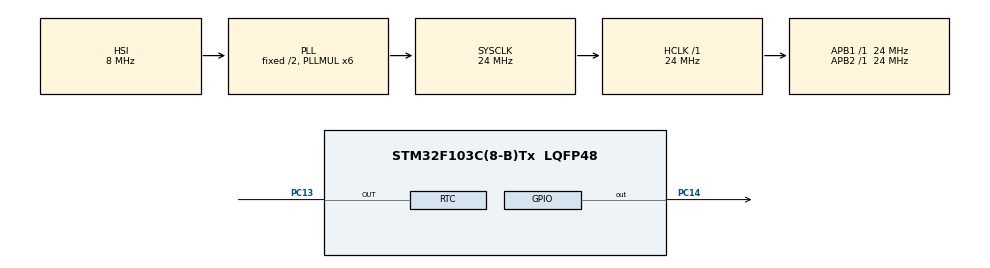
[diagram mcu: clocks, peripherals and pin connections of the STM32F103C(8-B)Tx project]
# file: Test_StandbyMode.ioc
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Mcu.Family=STM32F1
Mcu.Name=STM32F103C(8-B)Tx
Mcu.Package=LQFP48
NVIC.PriorityGroup=NVIC_PRIORITYGROUP_4
PA0-WKUP.Mode=SYS_WakeUp0
PA0-WKUP.Signal=SYS_WKUP
PA13.Mode=Serial_Wire
PA13.Signal=SYS_JTMS-SWDIO
PA14.Mode=Serial_Wire
PA14.Signal=SYS_JTCK-SWCLK
PC13-TAMPER-RTC.Mode=RTC OUT
PC13-TAMPER-RTC.Signal=RTC_OUT
PC14-OSC32_IN.Signal=GPIO_Output
ProjectManager.HeapSize=0x200
ProjectManager.StackSize=0x400
ProjectManager.TargetToolchain=MDK-ARM V5
RCC.AHBFreq_Value=24000000
RCC.APB1Freq_Value=24000000
RCC.APB1TimFreq_Value=24000000
RCC.APB2Freq_Value=24000000
RCC.APB2TimFreq_Value=24000000
RCC.HCLKFreq_Value=24000000
RCC.PLLMUL=RCC_PLL_MUL6
RCC.SYSCLKFreq_VALUE=24000000
RCC.SYSCLKSource=RCC_SYSCLKSOURCE_PLLCLK
RCC.USBFreq_Value=24000000
RTC.Format=RTC_FORMAT_BIN
RTC.Hours_A-RTC\ OUT=1
RTC.Seconds_A-RTC\ OUT=20
VP_RTC_VS_RTC_Activate.Mode=RTC_Enabled
board=Test_StandbyMode

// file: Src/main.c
/**
  ******************************************************************************
  * @file           : main.c
  * @brief          : Main program body
  ******************************************************************************
  ** This notice applies to any and all portions of this file
  * that are not between comment pairs USER CODE BEGIN and
  * USER CODE END. Other portions of this file, whether
  * inserted by the user or by software development tools
  * are owned by their respective copyright owners.
  *
  * COPYRIGHT(c) 2018 STMicroelectronics
  *
  * Redistribution and use in source and binary forms, with or without modification,
  * are permitted provided that the following conditions are met:
  *   1. Redistributions of source code must retain the above copyright notice,
  *      this list of conditions and the following disclaimer.
  *   2. Redistributions in binary form must reproduce the above copyright notice,
  *      this list of conditions and the following disclaimer in the documentation
  *      and/or other materials provided with the distribution.
  *   3. Neither the name of STMicroelectronics nor the names of its contributors
  *      may be used to endorse or promote products derived from this software
  *      without specific prior written permission.
  *
  * THIS SOFTWARE IS PROVIDED BY THE COPYRIGHT HOLDERS AND CONTRIBUTORS "AS IS"
  * AND ANY EXPRESS OR IMPLIED WARRANTIES, INCLUDING, BUT NOT LIMITED TO, THE
  * IMPLIED WARRANTIES OF MERCHANTABILITY AND FITNESS FOR A PARTICULAR PURPOSE ARE
  * DISCLAIMED. IN NO EVENT SHALL THE COPYRIGHT HOLDER OR CONTRIBUTORS BE LIABLE
  * FOR ANY DIRECT, INDIRECT, INCIDENTAL, SPECIAL, EXEMPLARY, OR CONSEQUENTIAL
  * DAMAGES (INCLUDING, BUT NOT LIMITED TO, PROCUREMENT OF SUBSTITUTE GOODS OR
  * SERVICES; LOSS OF USE, DATA, OR PROFITS; OR BUSINESS INTERRUPTION) HOWEVER
  * CAUSED AND ON ANY THEORY OF LIABILITY, WHETHER IN CONTRACT, STRICT LIABILITY,
  * OR TORT (INCLUDING NEGLIGENCE OR OTHERWISE) ARISING IN ANY WAY OUT OF THE USE
  * OF THIS SOFTWARE, EVEN IF ADVISED OF THE POSSIBILITY OF SUCH DAMAGE.
  *
  ******************************************************************************
  */
#include "main.h"
#include "stm32f1xx_hal.h"

RTC_HandleTypeDef hrtc;

/* USER CODE BEGIN PV */
/* Private variables ---------------------------------------------------------*/

/* USER CODE END PV */

void SystemClock_Config(void);
static void MX_GPIO_Init(void);
static void MX_RTC_Init(void);

/* USER CODE BEGIN PFP */
/* Private function prototypes -----------------------------------------------*/

/* USER CODE END PFP */

int main(void)
{

  /* MCU Configuration----------------------------------------------------------*/

  /* Reset of all peripherals, Initializes the Flash interface and the Systick. */
  HAL_Init();

  /* Configure the system clock */
  SystemClock_Config();

  /* Initialize all configured peripherals */
  MX_GPIO_Init();
  MX_RTC_Init();
  /* USER CODE BEGIN 2 */
//	DBGMCU->CR |= DBGMCU_CR_DBG_SLEEP;
//	DBGMCU->CR |= DBGMCU_CR_DBG_STOP;
//	DBGMCU->CR |= DBGMCU_CR_DBG_STANDBY;
	//---------------------------------
	HAL_GPIO_WritePin(GPIOC, GPIO_PIN_14, GPIO_PIN_SET);
	HAL_Delay(2000);
	__HAL_RCC_PWR_CLK_ENABLE();
	__HAL_PWR_CLEAR_FLAG(PWR_FLAG_WU);
	HAL_PWR_EnableWakeUpPin(PWR_WAKEUP_PIN1);
	HAL_PWR_EnterSTANDBYMode();
  /* USER CODE END 2 */

  /* Infinite loop */
  while (1)
  {

  }

}

void SystemClock_Config(void)
{

  RCC_OscInitTypeDef RCC_OscInitStruct;
  RCC_ClkInitTypeDef RCC_ClkInitStruct;
  RCC_PeriphCLKInitTypeDef PeriphClkInit;

    /**Initializes the CPU, AHB and APB busses clocks
    */
  RCC_OscInitStruct.OscillatorType = RCC_OSCILLATORTYPE_HSI|RCC_OSCILLATORTYPE_LSI;
  RCC_OscInitStruct.HSIState = RCC_HSI_ON;
  RCC_OscInitStruct.HSICalibrationValue = 16;
  RCC_OscInitStruct.LSIState = RCC_LSI_ON;
  RCC_OscInitStruct.PLL.PLLState = RCC_PLL_ON;
  RCC_OscInitStruct.PLL.PLLSource = RCC_PLLSOURCE_HSI_DIV2;
  RCC_OscInitStruct.PLL.PLLMUL = RCC_PLL_MUL6;
  if (HAL_RCC_OscConfig(&RCC_OscInitStruct) != HAL_OK)
  {
    _Error_Handler(__FILE__, __LINE__);
  }

    /**Initializes the CPU, AHB and APB busses clocks
    */
  RCC_ClkInitStruct.ClockType = RCC_CLOCKTYPE_HCLK|RCC_CLOCKTYPE_SYSCLK
                              |RCC_CLOCKTYPE_PCLK1|RCC_CLOCKTYPE_PCLK2;
  RCC_ClkInitStruct.SYSCLKSource = RCC_SYSCLKSOURCE_PLLCLK;
  RCC_ClkInitStruct.AHBCLKDivider = RCC_SYSCLK_DIV1;
  RCC_ClkInitStruct.APB1CLKDivider = RCC_HCLK_DIV1;
  RCC_ClkInitStruct.APB2CLKDivider = RCC_HCLK_DIV1;

  if (HAL_RCC_ClockConfig(&RCC_ClkInitStruct, FLASH_LATENCY_0) != HAL_OK)
  {
    _Error_Handler(__FILE__, __LINE__);
  }

  PeriphClkInit.PeriphClockSelection = RCC_PERIPHCLK_RTC;
  PeriphClkInit.RTCClockSelection = RCC_RTCCLKSOURCE_LSI;
  if (HAL_RCCEx_PeriphCLKConfig(&PeriphClkInit) != HAL_OK)
  {
    _Error_Handler(__FILE__, __LINE__);
  }

    /**Configure the Systick interrupt time
    */
  HAL_SYSTICK_Config(HAL_RCC_GetHCLKFreq()/1000);

    /**Configure the Systick
    */
  HAL_SYSTICK_CLKSourceConfig(SYSTICK_CLKSOURCE_HCLK);

  /* SysTick_IRQn interrupt configuration */
  HAL_NVIC_SetPriority(SysTick_IRQn, 0, 0);
}

/* RTC init function */
static void MX_RTC_Init(void)
{

  RTC_TimeTypeDef sTime;
  RTC_DateTypeDef DateToUpdate;
  RTC_AlarmTypeDef sAlarm;

    /**Initialize RTC Only
    */
  hrtc.Instance = RTC;
  if(HAL_RTCEx_BKUPRead(&hrtc, RTC_BKP_DR1) != 0x32F2){
  hrtc.Init.AsynchPrediv = RTC_AUTO_1_SECOND;
  hrtc.Init.OutPut = RTC_OUTPUTSOURCE_ALARM;
  if (HAL_RTC_Init(&hrtc) != HAL_OK)
  {
    _Error_Handler(__FILE__, __LINE__);
  }

    /**Initialize RTC and set the Time and Date
    */
  sTime.Hours = 1;
  sTime.Minutes = 0;
  sTime.Seconds = 0;

  if (HAL_RTC_SetTime(&hrtc, &sTime, RTC_FORMAT_BIN) != HAL_OK)
  {
    _Error_Handler(__FILE__, __LINE__);
  }

  DateToUpdate.WeekDay = RTC_WEEKDAY_MONDAY;
  DateToUpdate.Month = RTC_MONTH_JANUARY;
  DateToUpdate.Date = 1;
  DateToUpdate.Year = 0;

  if (HAL_RTC_SetDate(&hrtc, &DateToUpdate, RTC_FORMAT_BIN) != HAL_OK)
  {
    _Error_Handler(__FILE__, __LINE__);
  }

    /**Enable the Alarm A
    */
  sAlarm.AlarmTime.Hours = 1;
  sAlarm.AlarmTime.Minutes = 0;
  sAlarm.AlarmTime.Seconds = 20;
  sAlarm.Alarm = RTC_ALARM_A;
  if (HAL_RTC_SetAlarm(&hrtc, &sAlarm, RTC_FORMAT_BIN) != HAL_OK)
  {
    _Error_Handler(__FILE__, __LINE__);
  }

    HAL_RTCEx_BKUPWrite(&hrtc,RTC_BKP_DR1,0x32F2);
  }

}

/** Configure pins as
        * Analog
        * Input
        * Output
        * EVENT_OUT
        * EXTI
*/
static void MX_GPIO_Init(void)
{

  GPIO_InitTypeDef GPIO_InitStruct;

  /* GPIO Ports Clock Enable */
  __HAL_RCC_GPIOC_CLK_ENABLE();
  __HAL_RCC_GPIOA_CLK_ENABLE();

  /*Configure GPIO pin Output Level */
  HAL_GPIO_WritePin(GPIOC, GPIO_PIN_14, GPIO_PIN_RESET);

  /*Configure GPIO pin : PC14 */
  GPIO_InitStruct.Pin = GPIO_PIN_14;
  GPIO_InitStruct.Mode = GPIO_MODE_OUTPUT_PP;
  GPIO_InitStruct.Speed = GPIO_SPEED_FREQ_LOW;
  HAL_GPIO_Init(GPIOC, &GPIO_InitStruct);

}

void _Error_Handler(char *file, int line)
{
  while(1)
  {
  }
}

/************************ (C) COPYRIGHT STMicroelectronics *****END OF FILE****/
